AUTOSAR XML (schema 4-3-0)
package /ComponentTypes
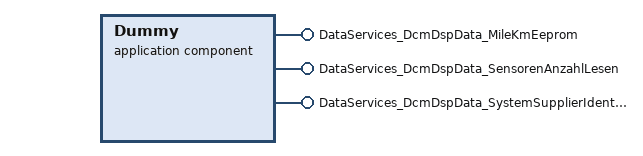
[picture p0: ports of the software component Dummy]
  application sw component type Dummy
    provide port DataServices_DcmDspData_MileKmEeprom: provided-com-specs=[{operation=ConditionCheckRead, queue-length=1}, {operation=ReadData, queue-length=1}], provided-interface=DataServices_DcmDspData_MileKmEeprom
    provide port DataServices_DcmDspData_SensorenAnzahlLesen: provided-com-specs=[{operation=ConditionCheckRead, queue-length=1}, {operation=ReadData, queue-length=1}], provided-interface=DataServices_DcmDspData_SensorenAnzahlLesen
    provide port DataServices_DcmDspData_SystemSupplierIdentifier: provided-com-specs=[{operation=ConditionCheckRead, queue-length=1}, {operation=ReadData, queue-length=1}], provided-interface=DataServices_DcmDspData_SystemSupplierIdentifier
    behavior Dummy_InternalBehavior: port-api-option{enable-take-address=false, error-handling=NO-TRANSFORMER-ERROR-HANDLING, indirect-api=false, port=DataServices_DcmDspData_MileKmEeprom}
      6 x operation invoked event:
        OIT_DataServices_DcmDspData_MileKmEeprom_ConditionCheckRead_DataServices_DcmDspData_MileKmEeprom_ConditionCheckRead: start-on-event=DataServices_DcmDspData_MileKmEeprom_ConditionCheckRead, operation=DataServices_DcmDspData_MileKmEeprom.ConditionCheckRead
        OIT_DataServices_DcmDspData_MileKmEeprom_ReadData_DataServices_DcmDspData_MileKmEeprom_ReadData: start-on-event=DataServices_DcmDspData_MileKmEeprom_ReadData, operation=DataServices_DcmDspData_MileKmEeprom.ReadData
        OIT_DataServices_DcmDspData_SensorenAnzahlLesen_ConditionCheckRead_DataServices_DcmDspData_SensorenAnzahlLesen_Condition055FF87D: start-on-event=DataServices_DcmDspData_SensorenAnzahlLesen_ConditionCheckRead, operation=DataServices_DcmDspData_SensorenAnzahlLesen.ConditionCheckRead
        OIT_DataServices_DcmDspData_SensorenAnzahlLesen_ReadData_DataServices_DcmDspData_SensorenAnzahlLesen_ReadData: start-on-event=DataServices_DcmDspData_SensorenAnzahlLesen_ReadData, operation=DataServices_DcmDspData_SensorenAnzahlLesen.ReadData
        OIT_DataServices_DcmDspData_SystemSupplierIdentifier_ConditionCheckRead_DataServices_DcmDspData_SystemSupplierIdentifier335977C2: start-on-event=DataServices_DcmDspData_SystemSupplierIdentifier_ConditionCheckRead, operation=DataServices_DcmDspData_SystemSupplierIdentifier.ConditionCheckRead
        OIT_DataServices_DcmDspData_SystemSupplierIdentifier_ReadData_DataServices_DcmDspData_SystemSupplierIdentifier_ReadData: start-on-event=DataServices_DcmDspData_SystemSupplierIdentifier_ReadData, operation=DataServices_DcmDspData_SystemSupplierIdentifier.ReadData
      6 x runnable:
        DataServices_DcmDspData_MileKmEeprom_ConditionCheckRead
        DataServices_DcmDspData_MileKmEeprom_ReadData
        DataServices_DcmDspData_SensorenAnzahlLesen_ConditionCheckRead
        DataServices_DcmDspData_SensorenAnzahlLesen_ReadData
        DataServices_DcmDspData_SystemSupplierIdentifier_ConditionCheckRead
        DataServices_DcmDspData_SystemSupplierIdentifier_ReadData
  swc implementation Dummy_Implementation: behavior=Dummy_InternalBehavior
    code-descriptors:
      code Default: artifact-descriptors=autosar-engineering-object={short-label=Default, category=SWSRC}
